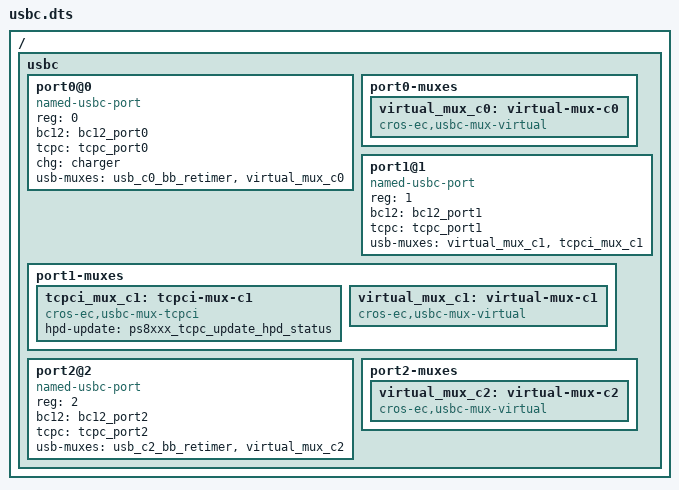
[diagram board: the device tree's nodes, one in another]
/* Copyright 2022 The Chromium OS Authors. All rights reserved.
 * Use of this source code is governed by a BSD-style license that can be
 * found in the LICENSE file.
 */

/ {
	usbc {
		#address-cells = <1>;
		#size-cells = <0>;

		port0@0 {
			compatible = "named-usbc-port";
			reg = <0>;
			bc12 = <&bc12_port0>;
			tcpc = <&tcpc_port0>;
			chg = <&charger>;
			usb-muxes = <&usb_c0_bb_retimer &virtual_mux_c0>;
		};
		port0-muxes {
			virtual_mux_c0: virtual-mux-c0 {
				compatible = "cros-ec,usbc-mux-virtual";
			};
		};

		port1@1 {
			compatible = "named-usbc-port";
			reg = <1>;
			bc12 = <&bc12_port1>;
			tcpc = <&tcpc_port1>;
			usb-muxes = <&virtual_mux_c1 &tcpci_mux_c1>;
		};
		port1-muxes {
			tcpci_mux_c1: tcpci-mux-c1 {
				compatible = "cros-ec,usbc-mux-tcpci";
				hpd-update = "ps8xxx_tcpc_update_hpd_status";
			};
			virtual_mux_c1: virtual-mux-c1 {
				compatible = "cros-ec,usbc-mux-virtual";
			};
		};

		port2@2 {
			compatible = "named-usbc-port";
			reg = <2>;
			bc12 = <&bc12_port2>;
			tcpc = <&tcpc_port2>;
			usb-muxes = <&usb_c2_bb_retimer &virtual_mux_c2>;
		};
		port2-muxes {
			virtual_mux_c2: virtual-mux-c2 {
				compatible = "cros-ec,usbc-mux-virtual";
			};
		};
	};
};
